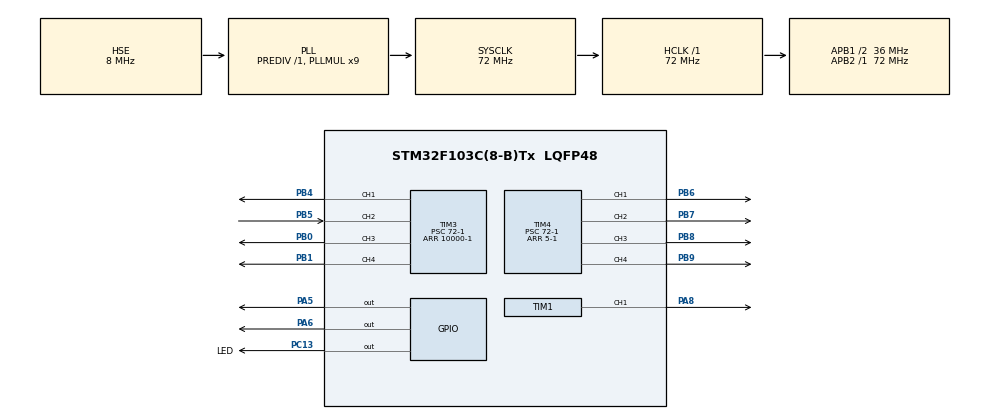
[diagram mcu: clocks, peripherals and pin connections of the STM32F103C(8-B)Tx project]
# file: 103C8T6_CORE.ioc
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Mcu.Family=STM32F1
Mcu.Name=STM32F103C(8-B)Tx
Mcu.Package=LQFP48
NVIC.PriorityGroup=NVIC_PRIORITYGROUP_4
NVIC.TIM2_IRQn=true\:0\:0\:false\:false\:true\:true\:true\:true
NVIC.TIM3_IRQn=true\:0\:0\:false\:false\:true\:true\:true\:true
NVIC.TIM4_IRQn=true\:0\:0\:false\:false\:true\:true\:true\:true
PA13.Mode=Serial_Wire
PA13.Signal=SYS_JTMS-SWDIO
PA14.Mode=Serial_Wire
PA14.Signal=SYS_JTCK-SWCLK
PA5.GPIO_PuPd=GPIO_PULLUP
PA5.GPIO_Speed=GPIO_SPEED_FREQ_MEDIUM
PA5.PinState=GPIO_PIN_SET
PA5.Signal=GPIO_Output
PA6.GPIO_PuPd=GPIO_PULLDOWN
PA6.GPIO_Speed=GPIO_SPEED_FREQ_MEDIUM
PA6.Signal=GPIO_Output
PA8.Signal=S_TIM1_CH1
PB0.Signal=S_TIM3_CH3
PB1.Signal=S_TIM3_CH4
PB4.Signal=S_TIM3_CH1
PB5.Signal=S_TIM3_CH2
PB6.Signal=S_TIM4_CH1
PB7.Signal=S_TIM4_CH2
PB8.Signal=S_TIM4_CH3
PB9.Signal=S_TIM4_CH4
PC13-TAMPER-RTC.GPIO_Label=LED
PC13-TAMPER-RTC.Signal=GPIO_Output
PD0-OSC_IN.Mode=HSE-External-Oscillator
PD0-OSC_IN.Signal=RCC_OSC_IN
PD1-OSC_OUT.Mode=HSE-External-Oscillator
PD1-OSC_OUT.Signal=RCC_OSC_OUT
ProjectManager.HeapSize=0x200
ProjectManager.StackSize=0x400
ProjectManager.TargetToolchain=MDK-ARM V5.32
RCC.AHBFreq_Value=72000000
RCC.APB1CLKDivider=RCC_HCLK_DIV2
RCC.APB1Freq_Value=36000000
RCC.APB1TimFreq_Value=72000000
RCC.APB2Freq_Value=72000000
RCC.APB2TimFreq_Value=72000000
RCC.HCLKFreq_Value=72000000
RCC.PLLMUL=RCC_PLL_MUL9
RCC.PLLSourceVirtual=RCC_PLLSOURCE_HSE
RCC.SYSCLKFreq_VALUE=72000000
RCC.SYSCLKSource=RCC_SYSCLKSOURCE_PLLCLK
RCC.USBFreq_Value=72000000
SH.S_TIM1_CH1.0=TIM1_CH1,PWM Generation1 CH1
SH.S_TIM3_CH1.0=TIM3_CH1,Output Compare1 CH1
SH.S_TIM3_CH2.0=TIM3_CH2,Input_Capture2_from_TI2
SH.S_TIM3_CH3.0=TIM3_CH3,PWM Generation3 CH3
SH.S_TIM3_CH4.0=TIM3_CH4,PWM Generation4 CH4
SH.S_TIM4_CH1.0=TIM4_CH1,PWM Generation1 CH1
SH.S_TIM4_CH2.0=TIM4_CH2,PWM Generation2 CH2
SH.S_TIM4_CH3.0=TIM4_CH3,PWM Generation3 CH3
SH.S_TIM4_CH4.0=TIM4_CH4,PWM Generation4 CH4
TIM1.AutoReloadPreload=TIM_AUTORELOAD_PRELOAD_ENABLE
TIM1.Channel-PWM\ Generation1\ CH1=TIM_CHANNEL_1
TIM1.Period=12500-1
TIM1.Prescaler=72-1
TIM1.Pulse-PWM\ Generation1\ CH1=6250
TIM2.AutoReloadPreload=TIM_AUTORELOAD_PRELOAD_ENABLE
TIM2.Period=5-1
TIM2.Prescaler=72-1
TIM3.AutoReloadPreload=TIM_AUTORELOAD_PRELOAD_ENABLE
TIM3.Channel-Input_Capture2_from_TI2=TIM_CHANNEL_2
TIM3.Channel-Output\ Compare1\ CH1=TIM_CHANNEL_1
TIM3.Channel-PWM\ Generation3\ CH3=TIM_CHANNEL_3
TIM3.Channel-PWM\ Generation4\ CH4=TIM_CHANNEL_4
TIM3.OC1Preload=ENABLE
TIM3.OCMode_1=TIM_OCMODE_TOGGLE
TIM3.Period=10000-1
TIM3.Prescaler=72-1
TIM3.Pulse-Output\ Compare1\ CH1=1000-1
TIM3.Pulse-PWM\ Generation3\ CH3=5000
TIM3.Pulse-PWM\ Generation4\ CH4=2000
TIM4.AutoReloadPreload=TIM_AUTORELOAD_PRELOAD_ENABLE
TIM4.Channel-PWM\ Generation1\ CH1=TIM_CHANNEL_1
TIM4.Channel-PWM\ Generation2\ CH2=TIM_CHANNEL_2
TIM4.Channel-PWM\ Generation3\ CH3=TIM_CHANNEL_3
TIM4.Channel-PWM\ Generation4\ CH4=TIM_CHANNEL_4
TIM4.Period=5-1
TIM4.Prescaler=72-1
TIM4.Pulse-PWM\ Generation1\ CH1=2
TIM4.Pulse-PWM\ Generation2\ CH2=2
TIM4.Pulse-PWM\ Generation3\ CH3=2
TIM4.Pulse-PWM\ Generation4\ CH4=2
VP_TIM1_VS_ClockSourceINT.Mode=Internal
VP_TIM2_VS_ClockSourceINT.Mode=Internal
VP_TIM3_VS_ClockSourceINT.Mode=Internal
VP_TIM4_VS_ClockSourceINT.Mode=Internal
board=custom

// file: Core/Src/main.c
/* USER CODE BEGIN Header */
/**
  ******************************************************************************
  * @file           : main.c
  * @brief          : Main program body
  ******************************************************************************
  * @attention
  *
  * Copyright (c) 2024 STMicroelectronics.
  * All rights reserved.
  *
  * This software is licensed under terms that can be found in the LICENSE file
  * in the root directory of this software component.
  * If no LICENSE file comes with this software, it is provided AS-IS.
  *
  ******************************************************************************
  */
/* USER CODE END Header */
#include "main.h"
#include "tim.h"
#include "gpio.h"

void SystemClock_Config(void);

int main(void)
{

  /* MCU Configuration--------------------------------------------------------*/

  /* Reset of all peripherals, Initializes the Flash interface and the Systick. */
  HAL_Init();

  /* Configure the system clock */
  SystemClock_Config();

  /* Initialize all configured peripherals */
  MX_GPIO_Init();
  MX_TIM1_Init();
  MX_TIM3_Init();
  MX_TIM4_Init();
  MX_TIM2_Init();
  /* USER CODE BEGIN 2 */
	HAL_TIM_PWM_Start(&htim1,TIM_CHANNEL_1);
//  HAL_TIM_OC_Start(&htim3,TIM_CHANNEL_1);
//  HAL_TIM_IC_Start_IT(&htim3,TIM_CHANNEL_2);
//	HAL_TIM_PWM_Start(&htim3,TIM_CHANNEL_3);
//	HAL_TIM_PWM_Start(&htim3,TIM_CHANNEL_4);
//	HAL_TIM_PWM_Start(&htim4,TIM_CHANNEL_1);
//	HAL_TIM_PWM_Start(&htim4,TIM_CHANNEL_2);
//	HAL_TIM_PWM_Start(&htim4,TIM_CHANNEL_3);
//	HAL_TIM_PWM_Start(&htim4,TIM_CHANNEL_4);
	HAL_TIM_Base_Start_IT(&htim2);
  /* USER CODE END 2 */

  /* Infinite loop */
  while (1)
  {

    /* USER CODE BEGIN 3 */
		HAL_GPIO_TogglePin(GPIOC,GPIO_PIN_13);

		HAL_Delay(1000);
  }
  /* USER CODE END 3 */
}

void SystemClock_Config(void)
{
  RCC_OscInitTypeDef RCC_OscInitStruct = {0};
  RCC_ClkInitTypeDef RCC_ClkInitStruct = {0};

  /** Initializes the RCC Oscillators according to the specified parameters
  * in the RCC_OscInitTypeDef structure.
  */
  RCC_OscInitStruct.OscillatorType = RCC_OSCILLATORTYPE_HSE;
  RCC_OscInitStruct.HSEState = RCC_HSE_ON;
  RCC_OscInitStruct.HSEPredivValue = RCC_HSE_PREDIV_DIV1;
  RCC_OscInitStruct.HSIState = RCC_HSI_ON;
  RCC_OscInitStruct.PLL.PLLState = RCC_PLL_ON;
  RCC_OscInitStruct.PLL.PLLSource = RCC_PLLSOURCE_HSE;
  RCC_OscInitStruct.PLL.PLLMUL = RCC_PLL_MUL9;
  if (HAL_RCC_OscConfig(&RCC_OscInitStruct) != HAL_OK)
  {
    Error_Handler();
  }

  /** Initializes the CPU, AHB and APB buses clocks
  */
  RCC_ClkInitStruct.ClockType = RCC_CLOCKTYPE_HCLK|RCC_CLOCKTYPE_SYSCLK
                              |RCC_CLOCKTYPE_PCLK1|RCC_CLOCKTYPE_PCLK2;
  RCC_ClkInitStruct.SYSCLKSource = RCC_SYSCLKSOURCE_PLLCLK;
  RCC_ClkInitStruct.AHBCLKDivider = RCC_SYSCLK_DIV1;
  RCC_ClkInitStruct.APB1CLKDivider = RCC_HCLK_DIV2;
  RCC_ClkInitStruct.APB2CLKDivider = RCC_HCLK_DIV1;

  if (HAL_RCC_ClockConfig(&RCC_ClkInitStruct, FLASH_LATENCY_2) != HAL_OK)
  {
    Error_Handler();
  }
}

void Error_Handler(void)
{
  __disable_irq();
  while (1)
  {
  }
}
